# tmpm373 register map
File version: 0.1
TOSHIBA Cortex-M3 MCU
CPU: CM3 r2p0, little endian, no MPU, no FPU, 4 interrupt priority bits
Registers are 32-bit, read-write, reset 0x0 unless marked. A register's access mark holds for its fields unless they carry their own. Offsets are from the block's base; lines under a group give offsets from that group; [hi:lo] are bit positions; {n}, {i} and the like mark numbered series; 'fields as' and 'values as' point back to an identical list; <NAME> marks a mode.

## Memory map
0x40000000 PA blocks up to offset 0x3C — General Purpose Input_Output Port (PA)
0x40000040 PB blocks up to offset 0x3C — General Purpose Input_Output Port (PB)
0x400000C0 PD blocks up to offset 0x3C — General Purpose Input_Output Port (PD)
0x40000100 PE blocks up to offset 0x3C — General Purpose Input_Output Port (PE)
0x40000140 PF blocks up to offset 0x3C — General Purpose Input_Output Port (PF)
0x40000180 PG blocks up to offset 0x3C — General Purpose Input_Output Port (PG)
0x40000200 PI blocks up to offset 0x3C — General Purpose Input_Output Port (PI)
0x40000240 PJ blocks up to offset 0x3C — General Purpose Input_Output Port (PJ)
0x40000280 PK blocks up to offset 0x3C — General Purpose Input_Output Port (PK)
0x40000300 PM blocks up to offset 0x3C — General Purpose Input_Output Port (PM)
0x40010000 TB0 size 0x30 — 16-bit Timer_Event Counter (TB)
0x40010040 TB1 size 0x30
0x40010080 TB2 size 0x30
0x400100C0 TB3 size 0x30
0x40010100 TB4 size 0x30
0x40010140 TB5 size 0x30
0x40010180 TB6 size 0x30
0x400101C0 TB7 size 0x30
0x40010500 EN size 0x10 — Encoder Input (ENC)
0x40020080 SC0 size 0x34 — Serial Channel (SC)
0x400200C0 SC1 size 0x34
0x40020140 SC3 size 0x34
0x40030200 AD blocks up to offset 0xD4 — Analog-to-Digital Converter (AD)
0x40040000 WD size 0x8 — Watchdog Timer (WD)
0x40040200 CG blocks up to offset 0x30 — Clock Generator (CG)
0x40040800 OFD size 0x18 — Oscillation Frequency Detector (OFD)
0x40040900 VD size 0x4 — Power-On Reset Circuit (POR)
0x40050000 VE blocks up to offset 0x1BC — Vector Engine (VE)
0x40050480 PMD size 0x64 — 16-bit Multi-Purpose Timer (MPT-PMD)
0x41FFF010 FC blocks up to offset 0x14 — Flash Control (FC)

## PA — General Purpose Input_Output Port (PA)
Base 0x40000000
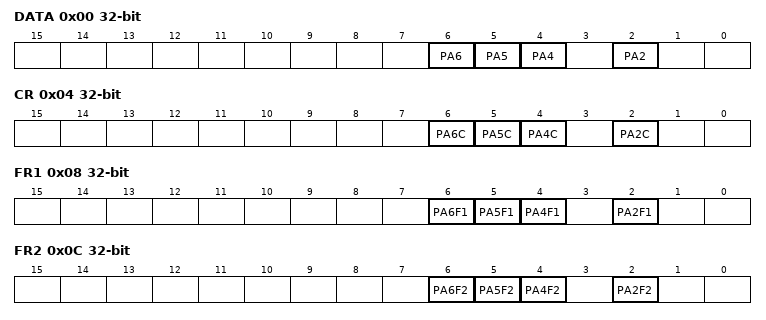
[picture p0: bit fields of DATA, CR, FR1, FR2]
0x00 DATA — PA Register
  [6] PA6, [5] PA5, [4] PA4, [2] PA2
0x04 CR — PA Control Register
  [6] PA6C, [5] PA5C, [4] PA4C, [2] PA2C
0x08 FR1 — PA Function Register 1
  [6] PA6F1, [5] PA5F1, [4] PA4F1, [2] PA2F1
0x0C FR2 — PA Function Register 2
  [6] PA6F2, [5] PA5F2, [4] PA4F2, [2] PA2F2
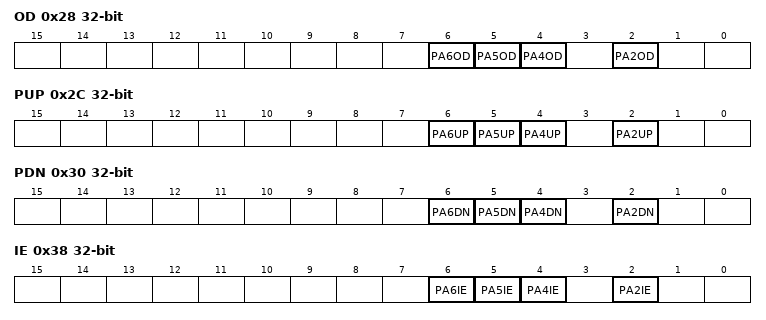
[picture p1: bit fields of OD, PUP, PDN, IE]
0x28 OD — PA Open Drain Control Register
  [6] PA6OD, [5] PA5OD, [4] PA4OD, [2] PA2OD
0x2C PUP — PA Pull-Up Control Register
  [6] PA6UP, [5] PA5UP, [4] PA4UP, [2] PA2UP
0x30 PDN — PA Pull-Down Control Register
  [6] PA6DN, [5] PA5DN, [4] PA4DN, [2] PA2DN
0x38 IE — PA Input Enable Control Register
  [6] PA6IE, [5] PA5IE, [4] PA4IE, [2] PA2IE

## PB — General Purpose Input_Output Port (PB)
Base 0x40000040
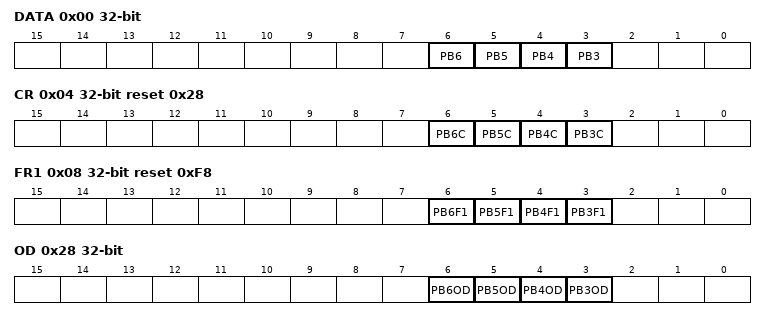
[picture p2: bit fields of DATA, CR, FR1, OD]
0x00 DATA — PB Register
  [n] PB{n} (n=3..6)
0x04 CR reset 0x28 — PB Control Register
  [n] PB{n}C (n=3..6)
0x08 FR1 reset 0xF8 — PB Function Register 1
  [n] PB{n}F1 (n=3..6)
0x28 OD — PA Open Drain Control Register
  [n] PB{n}OD (n=3..6)
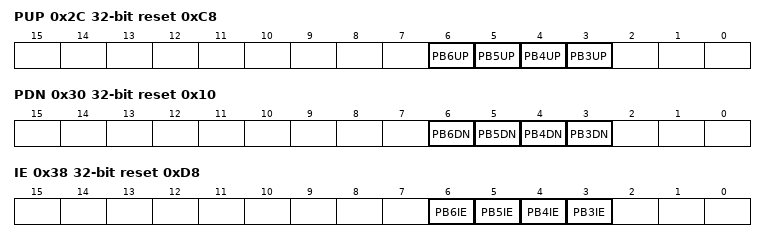
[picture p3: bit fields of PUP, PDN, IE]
0x2C PUP reset 0xC8 — PB Pull-Up Control Register
  [n] PB{n}UP (n=3..6)
0x30 PDN reset 0x10 — PB Pull-Down Control Register
  [n] PB{n}DN (n=3..6)
0x38 IE reset 0xD8 — PB Input Enable Control Register
  [n] PB{n}IE (n=3..6)

## PD — General Purpose Input_Output Port (PD)
Base 0x400000C0
0x00 DATA — PD Register
  [6] PD6
0x04 CR — PD Control Register
  [6] PD6C
0x08 FR1 — PD Function Register 1
  [6] PD6F1
0x0C FR2 — PD Function Register 2
0x28 OD — PD Open Drain Control Register
  [6] PD6OD
0x2C PUP — PD Pull-Up Control Register
  [6] PD6UP
0x30 PDN — PD Pull-Down Control Register
  [6] PD6DN
0x38 IE — PD Input Enable Control Register
  [6] PD6IE

## PE — General Purpose Input_Output Port (PE)
Base 0x40000100
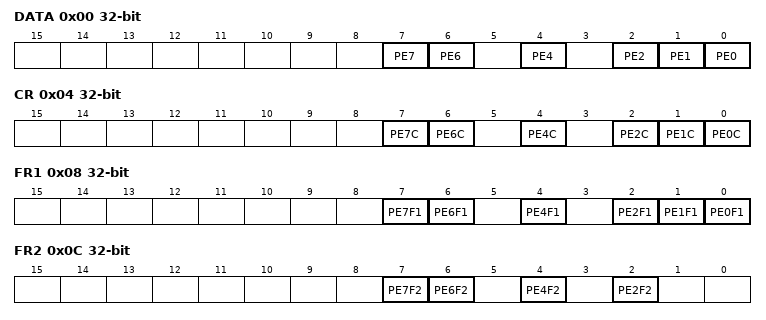
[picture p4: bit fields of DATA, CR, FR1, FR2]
0x00 DATA — PE Register
  [7] PE7, [6] PE6, [4] PE4, [2] PE2, [1] PE1, [0] PE0
0x04 CR — PE Control Register
  [7] PE7C, [6] PE6C, [4] PE4C, [2] PE2C, [1] PE1C, [0] PE0C
0x08 FR1 — PE Function Register 1
  [7] PE7F1, [6] PE6F1, [4] PE4F1, [2] PE2F1, [1] PE1F1, [0] PE0F1
0x0C FR2 — PE Function Register 2
  [7] PE7F2, [6] PE6F2, [4] PE4F2, [2] PE2F2
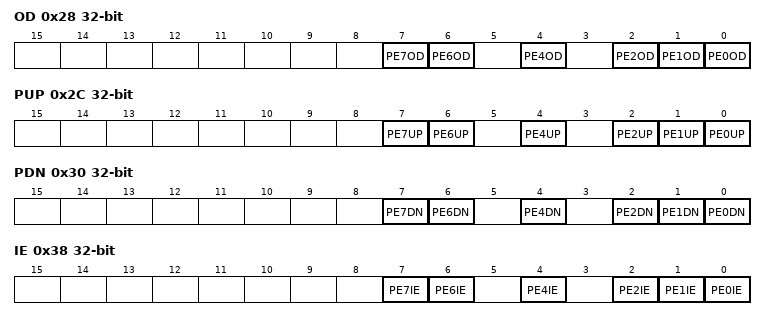
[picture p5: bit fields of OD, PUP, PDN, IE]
0x28 OD — PE Open Drain Control Register
  [7] PE7OD, [6] PE6OD, [4] PE4OD, [2] PE2OD, [1] PE1OD, [0] PE0OD
0x2C PUP — PE Pull-Up Control Register
  [7] PE7UP, [6] PE6UP, [4] PE4UP, [2] PE2UP, [1] PE1UP, [0] PE0UP
0x30 PDN — PE Pull-Down Control Register
  [7] PE7DN, [6] PE6DN, [4] PE4DN, [2] PE2DN, [1] PE1DN, [0] PE0DN
0x38 IE — PE Input Enable Control Register
  [7] PE7IE, [6] PE6IE, [4] PE4IE, [2] PE2IE, [1] PE1IE, [0] PE0IE
